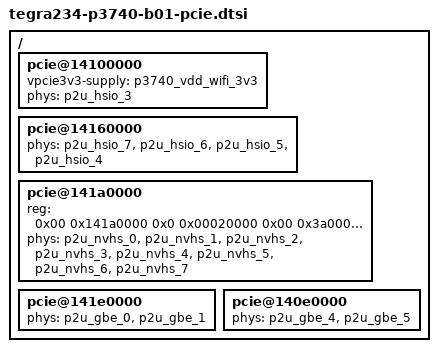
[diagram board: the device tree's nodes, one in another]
/*
 * Copyright (c) 2022, NVIDIA CORPORATION.  All rights reserved.
 *
 * This program is free software; you can redistribute it and/or modify
 * it under the terms of the GNU General Public License as published by
 * the Free Software Foundation; version 2 of the License.
 *
 * This program is distributed in the hope that it will be useful, but WITHOUT
 * ANY WARRANTY; without even the implied warranty of MERCHANTABILITY or
 * FITNESS FOR A PARTICULAR PURPOSE.  See the GNU General Public License for
 * more details.
 */

/ {

	/* PCIe-C1: 6-Lane PCIe Switch */
	pcie@14100000 {
		status = "okay";
		vpcie3v3-supply = <&p3740_vdd_wifi_3v3>;
		phys = <&p2u_hsio_3>;
		phy-names = "p2u-0";
	};

	/* PCIe-C4: M.2 Key-M NVMe */
	pcie@14160000 {
		status = "okay";

		phys = <&p2u_hsio_7>, <&p2u_hsio_6>, <&p2u_hsio_5>,
		       <&p2u_hsio_4>;
		phy-names = "p2u-0", "p2u-1", "p2u-2", "p2u-3";
	};

	/* PCIe-C5: CX7 */
	pcie@141a0000 {
		status = "okay";

		reg = <0x00 0x141a0000 0x0 0x00020000   /* appl registers (128K)      */
		       0x00 0x3a000000 0x0 0x00040000   /* configuration space (256K) */
		       0x00 0x3a040000 0x0 0x00040000   /* iATU_DMA reg space (256K)  */
		       0x00 0x3a080000 0x0 0x00040000   /* DBI reg space (256K)       */
		       0x2e 0x20000000 0x0 0x10000000>; /* ECAM (256MB)               */

		ranges = <0x81000000 0x00 0x3a100000 0x00 0x3a100000 0x0 0x00100000      /* downstream I/O (1MB) */
			  0x82000000 0x00 0x40000000 0x2e 0x30000000 0x0 0x08000000      /* non-prefetchable memory (128MB) */
			  0xc3000000 0x27 0x40000000 0x27 0x40000000 0x6 0xe0000000>;    /* prefetchable memory (28160MB) */

		phys = <&p2u_nvhs_0>, <&p2u_nvhs_1>, <&p2u_nvhs_2>,
		       <&p2u_nvhs_3>, <&p2u_nvhs_4>, <&p2u_nvhs_5>,
		       <&p2u_nvhs_6>, <&p2u_nvhs_7>;
		phy-names = "p2u-0", "p2u-1", "p2u-2", "p2u-3", "p2u-4",
			    "p2u-5", "p2u-6", "p2u-7";
	};

	/* PCIe-C7: SATA CTLR */
	pcie@141e0000 {
		status = "okay";

		phys = <&p2u_gbe_0>, <&p2u_gbe_1>;
		phy-names = "p2u-0", "p2u-1";
	};

	/* PCIe-C10: M.2 Key-M NVMe */
	pcie@140e0000 {
		status = "okay";

		phys = <&p2u_gbe_4>, <&p2u_gbe_5>;
		phy-names = "p2u-0", "p2u-1";
	};
};
